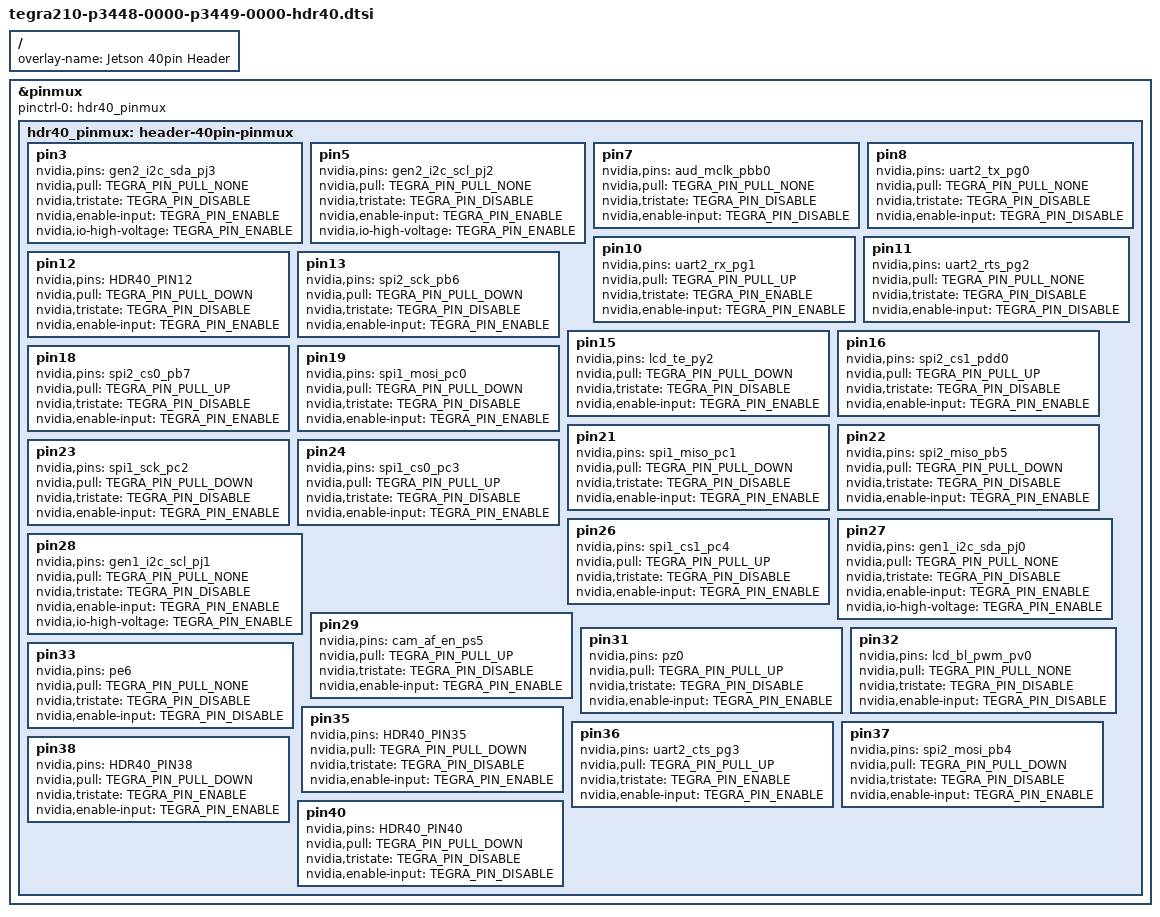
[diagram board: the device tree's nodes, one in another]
// SPDX-License-Identifier: GPL-2.0-only
/*
 * Common overlay DTSI for tegra210-p3448-0000-p3449-0000-* 40-pin
 * Expansion Header.
 *
 * Copyright (c) 2020 NVIDIA CORPORATION. All rights reserved.
 *
 */

/dts-v1/;
/plugin/;

#include <dt-bindings/pinctrl/pinctrl-tegra.h>

/ {
	overlay-name = "Jetson 40pin Header";
	compatible = JETSON_COMPATIBLE;

	fragment@0 {
		target = <&pinmux>;
		__overlay__ {
			pinctrl-names = "default";
			pinctrl-0 = <&hdr40_pinmux>;
			hdr40_pinmux: header-40pin-pinmux {
				pin3 {
					nvidia,pins = "gen2_i2c_sda_pj3";
					nvidia,pull = <TEGRA_PIN_PULL_NONE>;
					nvidia,tristate = <TEGRA_PIN_DISABLE>;
					nvidia,enable-input = <TEGRA_PIN_ENABLE>;
					nvidia,io-high-voltage = <TEGRA_PIN_ENABLE>;
				};
				pin5 {
					nvidia,pins = "gen2_i2c_scl_pj2";
					nvidia,pull = <TEGRA_PIN_PULL_NONE>;
					nvidia,tristate = <TEGRA_PIN_DISABLE>;
					nvidia,enable-input = <TEGRA_PIN_ENABLE>;
					nvidia,io-high-voltage = <TEGRA_PIN_ENABLE>;
				};
				pin7 {
					nvidia,pins = "aud_mclk_pbb0";
					nvidia,pull = <TEGRA_PIN_PULL_NONE>;
					nvidia,tristate = <TEGRA_PIN_DISABLE>;
					nvidia,enable-input = <TEGRA_PIN_DISABLE>;
				};
				pin8 {
					nvidia,pins = "uart2_tx_pg0";
					nvidia,pull = <TEGRA_PIN_PULL_NONE>;
					nvidia,tristate = <TEGRA_PIN_DISABLE>;
					nvidia,enable-input = <TEGRA_PIN_DISABLE>;
				};
				pin10 {
					nvidia,pins = "uart2_rx_pg1";
					nvidia,pull = <TEGRA_PIN_PULL_UP>;
					nvidia,tristate = <TEGRA_PIN_ENABLE>;
					nvidia,enable-input = <TEGRA_PIN_ENABLE>;
				};
				pin11 {
					nvidia,pins = "uart2_rts_pg2";
					nvidia,pull = <TEGRA_PIN_PULL_NONE>;
					nvidia,tristate = <TEGRA_PIN_DISABLE>;
					nvidia,enable-input = <TEGRA_PIN_DISABLE>;
				};
				pin12 {
					nvidia,pins = HDR40_PIN12;
					nvidia,pull = <TEGRA_PIN_PULL_DOWN>;
					nvidia,tristate = <TEGRA_PIN_DISABLE>;
					nvidia,enable-input = <TEGRA_PIN_ENABLE>;
				};
				pin13 {
					nvidia,pins = "spi2_sck_pb6";
					nvidia,pull = <TEGRA_PIN_PULL_DOWN>;
					nvidia,tristate = <TEGRA_PIN_DISABLE>;
					nvidia,enable-input = <TEGRA_PIN_ENABLE>;
				};
				pin15 {
					nvidia,pins = "lcd_te_py2";
					nvidia,pull = <TEGRA_PIN_PULL_DOWN>;
					nvidia,tristate = <TEGRA_PIN_DISABLE>;
					nvidia,enable-input = <TEGRA_PIN_ENABLE>;
				};
				pin16 {
					nvidia,pins = "spi2_cs1_pdd0";
					nvidia,pull = <TEGRA_PIN_PULL_UP>;
					nvidia,tristate = <TEGRA_PIN_DISABLE>;
					nvidia,enable-input = <TEGRA_PIN_ENABLE>;
				};
				pin18 {
					nvidia,pins = "spi2_cs0_pb7";
					nvidia,pull = <TEGRA_PIN_PULL_UP>;
					nvidia,tristate = <TEGRA_PIN_DISABLE>;
					nvidia,enable-input = <TEGRA_PIN_ENABLE>;
				};
				pin19 {
					nvidia,pins = "spi1_mosi_pc0";
					nvidia,pull = <TEGRA_PIN_PULL_DOWN>;
					nvidia,tristate = <TEGRA_PIN_DISABLE>;
					nvidia,enable-input = <TEGRA_PIN_ENABLE>;
				};
				pin21 {
					nvidia,pins = "spi1_miso_pc1";
					nvidia,pull = <TEGRA_PIN_PULL_DOWN>;
					nvidia,tristate = <TEGRA_PIN_DISABLE>;
					nvidia,enable-input = <TEGRA_PIN_ENABLE>;
				};
				pin22 {
					nvidia,pins = "spi2_miso_pb5";
					nvidia,pull = <TEGRA_PIN_PULL_DOWN>;
					nvidia,tristate = <TEGRA_PIN_DISABLE>;
					nvidia,enable-input = <TEGRA_PIN_ENABLE>;
				};
				pin23 {
					nvidia,pins = "spi1_sck_pc2";
					nvidia,pull = <TEGRA_PIN_PULL_DOWN>;
					nvidia,tristate = <TEGRA_PIN_DISABLE>;
					nvidia,enable-input = <TEGRA_PIN_ENABLE>;
				};
				pin24 {
					nvidia,pins = "spi1_cs0_pc3";
					nvidia,pull = <TEGRA_PIN_PULL_UP>;
					nvidia,tristate = <TEGRA_PIN_DISABLE>;
					nvidia,enable-input = <TEGRA_PIN_ENABLE>;
				};
				pin26 {
					nvidia,pins = "spi1_cs1_pc4";
					nvidia,pull = <TEGRA_PIN_PULL_UP>;
					nvidia,tristate = <TEGRA_PIN_DISABLE>;
					nvidia,enable-input = <TEGRA_PIN_ENABLE>;
				};
				pin27 {
					nvidia,pins = "gen1_i2c_sda_pj0";
					nvidia,pull = <TEGRA_PIN_PULL_NONE>;
					nvidia,tristate = <TEGRA_PIN_DISABLE>;
					nvidia,enable-input = <TEGRA_PIN_ENABLE>;
					nvidia,io-high-voltage = <TEGRA_PIN_ENABLE>;
				};
				pin28 {
					nvidia,pins = "gen1_i2c_scl_pj1";
					nvidia,pull = <TEGRA_PIN_PULL_NONE>;
					nvidia,tristate = <TEGRA_PIN_DISABLE>;
					nvidia,enable-input = <TEGRA_PIN_ENABLE>;
					nvidia,io-high-voltage = <TEGRA_PIN_ENABLE>;
				};
				pin29 {
					nvidia,pins = "cam_af_en_ps5";
					nvidia,pull = <TEGRA_PIN_PULL_UP>;
					nvidia,tristate = <TEGRA_PIN_DISABLE>;
					nvidia,enable-input = <TEGRA_PIN_ENABLE>;
				};
				pin31 {
					nvidia,pins = "pz0";
					nvidia,pull = <TEGRA_PIN_PULL_UP>;
					nvidia,tristate = <TEGRA_PIN_DISABLE>;
					nvidia,enable-input = <TEGRA_PIN_ENABLE>;
				};
				pin32 {
					nvidia,pins = "lcd_bl_pwm_pv0";
					nvidia,pull = <TEGRA_PIN_PULL_NONE>;
					nvidia,tristate = <TEGRA_PIN_DISABLE>;
					nvidia,enable-input = <TEGRA_PIN_DISABLE>;
				};
				pin33 {
					nvidia,pins = "pe6";
					nvidia,pull = <TEGRA_PIN_PULL_NONE>;
					nvidia,tristate = <TEGRA_PIN_DISABLE>;
					nvidia,enable-input = <TEGRA_PIN_DISABLE>;
				};
				pin35 {
					nvidia,pins = HDR40_PIN35;
					nvidia,pull = <TEGRA_PIN_PULL_DOWN>;
					nvidia,tristate = <TEGRA_PIN_DISABLE>;
					nvidia,enable-input = <TEGRA_PIN_ENABLE>;
				};
				pin36 {
					nvidia,pins = "uart2_cts_pg3";
					nvidia,pull = <TEGRA_PIN_PULL_UP>;
					nvidia,tristate = <TEGRA_PIN_ENABLE>;
					nvidia,enable-input = <TEGRA_PIN_ENABLE>;
				};
				pin37 {
					nvidia,pins = "spi2_mosi_pb4";
					nvidia,pull = <TEGRA_PIN_PULL_DOWN>;
					nvidia,tristate = <TEGRA_PIN_DISABLE>;
					nvidia,enable-input = <TEGRA_PIN_ENABLE>;
				};
				pin38 {
					nvidia,pins = HDR40_PIN38;
					nvidia,pull = <TEGRA_PIN_PULL_DOWN>;
					nvidia,tristate = <TEGRA_PIN_ENABLE>;
					nvidia,enable-input = <TEGRA_PIN_ENABLE>;
				};
				pin40 {
					nvidia,pins = HDR40_PIN40;
					nvidia,pull = <TEGRA_PIN_PULL_DOWN>;
					nvidia,tristate = <TEGRA_PIN_DISABLE>;
					nvidia,enable-input = <TEGRA_PIN_DISABLE>;
				};
			};
		};
	};
};
